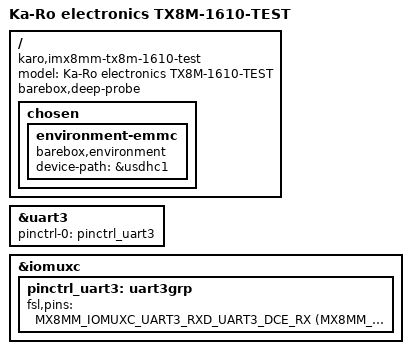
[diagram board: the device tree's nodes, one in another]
/dts-v1/;

#include "imx8mm-tx8m-1610.dtsi"

/ {
	model = "Ka-Ro electronics TX8M-1610-TEST";
	compatible = "karo,imx8mm-tx8m-1610-test", "karo,imx8mm-tx8m-1610", "fsl,imx8mm";
	barebox,deep-probe;

	chosen {
		environment-emmc {
			compatible = "barebox,environment";
			device-path = &usdhc1;
		};
	};
};

&uart3 {
	pinctrl-names = "default";
	pinctrl-0 = <&pinctrl_uart3>;
	status = "okay";
};

&iomuxc {
	pinctrl_uart3: uart3grp {
		fsl,pins = <
			MX8MM_IOMUXC_UART3_RXD_UART3_DCE_RX /* COM pin 62 */
			(MX8MM_PULL_UP | MX8MM_PULL_ENABLE)
			MX8MM_IOMUXC_UART3_TXD_UART3_DCE_TX /* COM pin 61 */
			(MX8MM_PULL_UP | MX8MM_PULL_ENABLE)
		>;
	};
};
